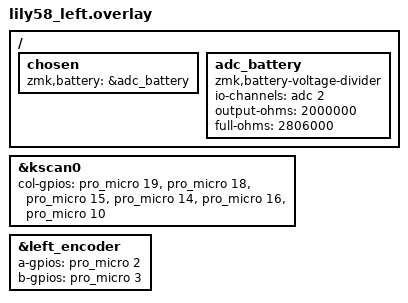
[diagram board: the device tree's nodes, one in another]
#include "lily58.dtsi"

&kscan0 {
    col-gpios
        = <&pro_micro 19 GPIO_ACTIVE_HIGH>
        , <&pro_micro 18 GPIO_ACTIVE_HIGH>
        , <&pro_micro 15 GPIO_ACTIVE_HIGH>
        , <&pro_micro 14 GPIO_ACTIVE_HIGH>
        , <&pro_micro 16 GPIO_ACTIVE_HIGH>
        , <&pro_micro 10 GPIO_ACTIVE_HIGH>
        ;
};

&left_encoder {
    status = "okay";
    /* Override pins - encoder in OLED header slots */
    a-gpios = <&pro_micro 2 (GPIO_ACTIVE_HIGH | GPIO_PULL_UP)>;
    b-gpios = <&pro_micro 3 (GPIO_ACTIVE_HIGH | GPIO_PULL_UP)>;
};

/ {
    chosen {
        zmk,battery = &adc_battery;
    };

    adc_battery: adc_battery {
        compatible = "zmk,battery-voltage-divider";
        io-channels = <&adc 2>;
        output-ohms = <2000000>;
        full-ohms = <2806000>;
    };
};
